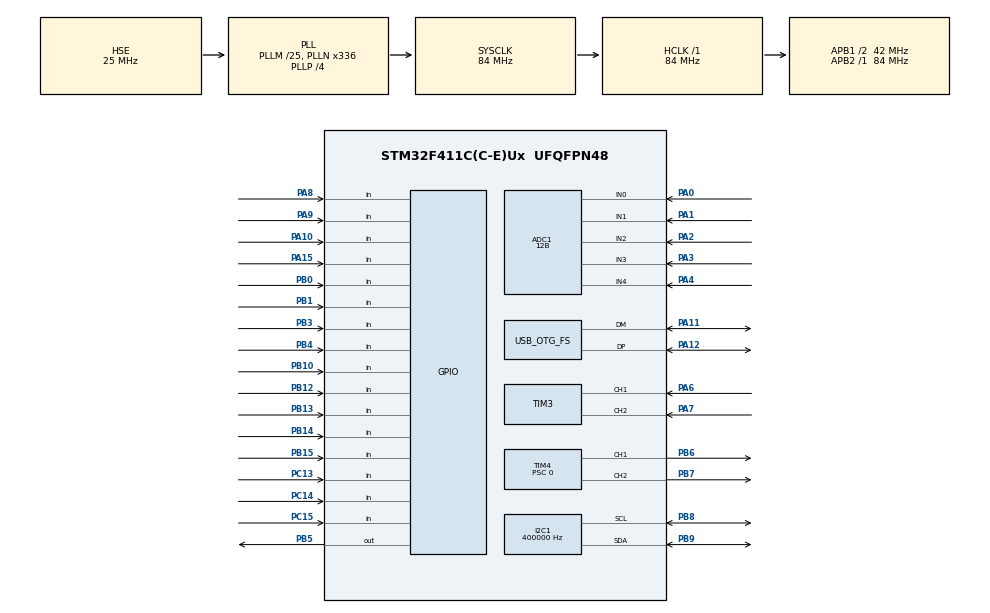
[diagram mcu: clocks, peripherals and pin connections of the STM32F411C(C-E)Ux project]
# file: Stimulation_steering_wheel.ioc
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ADC1.Channel-0\#ChannelRegularConversion=ADC_CHANNEL_0
ADC1.Channel-1\#ChannelRegularConversion=ADC_CHANNEL_1
ADC1.Channel-2\#ChannelRegularConversion=ADC_CHANNEL_2
ADC1.Channel-3\#ChannelRegularConversion=ADC_CHANNEL_3
ADC1.Channel-4\#ChannelRegularConversion=ADC_CHANNEL_4
ADC1.ClockPrescaler=ADC_CLOCK_SYNC_PCLK_DIV4
ADC1.ContinuousConvMode=DISABLE
ADC1.DMAContinuousRequests=DISABLE
ADC1.DataAlign=ADC_DATAALIGN_RIGHT
ADC1.DiscontinuousConvMode=DISABLE
ADC1.EOCSelection=ADC_EOC_SINGLE_CONV
ADC1.ExternalTrigConv=ADC_SOFTWARE_START
ADC1.ExternalTrigConvEdge=ADC_EXTERNALTRIGCONVEDGE_NONE
ADC1.NbrOfConversion=5
ADC1.NbrOfConversionFlag=1
ADC1.Rank-0\#ChannelRegularConversion=1
ADC1.Rank-1\#ChannelRegularConversion=2
ADC1.Rank-2\#ChannelRegularConversion=3
ADC1.Rank-3\#ChannelRegularConversion=4
ADC1.Rank-4\#ChannelRegularConversion=5
ADC1.Resolution=ADC_RESOLUTION_12B
ADC1.SamplingTime-0\#ChannelRegularConversion=ADC_SAMPLETIME_480CYCLES
ADC1.SamplingTime-1\#ChannelRegularConversion=ADC_SAMPLETIME_480CYCLES
ADC1.SamplingTime-2\#ChannelRegularConversion=ADC_SAMPLETIME_480CYCLES
ADC1.SamplingTime-3\#ChannelRegularConversion=ADC_SAMPLETIME_480CYCLES
ADC1.SamplingTime-4\#ChannelRegularConversion=ADC_SAMPLETIME_480CYCLES
ADC1.ScanConvMode=ENABLE
ADC1.master=1
I2C1.ClockSpeed=400000
I2C1.DutyCycle=I2C_DUTYCYCLE_2
I2C1.I2C_Mode=I2C_Fast
Mcu.Family=STM32F4
Mcu.Name=STM32F411C(C-E)Ux
Mcu.Package=UFQFPN48
NVIC.PriorityGroup=NVIC_PRIORITYGROUP_4
PA0-WKUP.Signal=ADCx_IN0
PA1.Signal=ADCx_IN1
PA10.GPIO_PuPd=GPIO_PULLUP
PA10.Signal=GPIO_Input
PA11.Mode=Device_Only
PA11.Signal=USB_OTG_FS_DM
PA12.Mode=Device_Only
PA12.Signal=USB_OTG_FS_DP
PA13.Mode=Serial_Wire
PA13.Signal=SYS_JTMS-SWDIO
PA14.Mode=Serial_Wire
PA14.Signal=SYS_JTCK-SWCLK
PA15.GPIO_PuPd=GPIO_PULLUP
PA15.Signal=GPIO_Input
PA2.Signal=ADCx_IN2
PA3.Signal=ADCx_IN3
PA4.Signal=ADCx_IN4
PA6.GPIO_PuPd=GPIO_PULLUP
PA6.Signal=S_TIM3_CH1
PA7.GPIO_PuPd=GPIO_PULLUP
PA7.Signal=S_TIM3_CH2
PA8.GPIO_PuPd=GPIO_PULLUP
PA8.Signal=GPIO_Input
PA9.GPIO_PuPd=GPIO_PULLUP
PA9.Signal=GPIO_Input
PB12.GPIO_PuPd=GPIO_PULLUP
PB12.Signal=GPIO_Input
PB13.GPIO_PuPd=GPIO_PULLUP
PB13.Signal=GPIO_Input
PB14.GPIO_PuPd=GPIO_PULLUP
PB14.Signal=GPIO_Input
PB15.GPIO_PuPd=GPIO_PULLUP
PB15.Signal=GPIO_Input
PB3.GPIO_PuPd=GPIO_PULLUP
PB3.Signal=GPIO_Input
PB4.GPIO_PuPd=GPIO_PULLUP
PB4.Signal=GPIO_Input
PB6.Signal=S_TIM4_CH1
PB7.Signal=S_TIM4_CH2
PB8.Mode=I2C
PB8.Signal=I2C1_SCL
PB9.Mode=I2C
PB9.Signal=I2C1_SDA
PB5.Signal=GPIO_Output
PH0\ -\ OSC_IN.Mode=HSE-External-Oscillator
PH0\ -\ OSC_IN.Signal=RCC_OSC_IN
PH1\ -\ OSC_OUT.Mode=HSE-External-Oscillator
PH1\ -\ OSC_OUT.Signal=RCC_OSC_OUT
ProjectManager.HeapSize=0x200
ProjectManager.StackSize=0x400
ProjectManager.TargetToolchain=MDK-ARM V5.32
RCC.48MHZClocksFreq_Value=48000000
RCC.AHBFreq_Value=84000000
RCC.APB1CLKDivider=RCC_HCLK_DIV2
RCC.APB1Freq_Value=42000000
RCC.APB1TimFreq_Value=84000000
RCC.APB2Freq_Value=84000000
RCC.APB2TimFreq_Value=84000000
RCC.CortexFreq_Value=84000000
RCC.HSE_VALUE=25000000
RCC.HSI_VALUE=16000000
RCC.LSE_VALUE=32768
RCC.PLLM=25
RCC.PLLN=336
RCC.PLLP=RCC_PLLP_DIV4
RCC.PLLQ=7
RCC.PLLSourceVirtual=RCC_PLLSOURCE_HSE
RCC.SYSCLKFreq_VALUE=84000000
RCC.SYSCLKSource=RCC_SYSCLKSOURCE_PLLCLK
RCC.VCOOutputFreq_Value=336000000
SH.ADCx_IN0.0=ADC1_IN0,IN0
SH.ADCx_IN1.0=ADC1_IN1,IN1
SH.ADCx_IN2.0=ADC1_IN2,IN2
SH.ADCx_IN3.0=ADC1_IN3,IN3
SH.ADCx_IN4.0=ADC1_IN4,IN4
SH.S_TIM3_CH1.0=TIM3_CH1,Encoder_Interface
SH.S_TIM3_CH2.0=TIM3_CH2,Encoder_Interface
SH.S_TIM4_CH1.0=TIM4_CH1,PWM Generation1 CH1
SH.S_TIM4_CH2.0=TIM4_CH2,PWM Generation2 CH2
TIM3.EncoderMode=TIM_ENCODERMODE_TI12
TIM3.IC1Filter=9
TIM3.IC1Prescaler=TIM_ICPSC_DIV1
TIM3.IC2Filter=9
TIM4.Channel-PWM\ Generation1\ CH1=TIM_CHANNEL_1
TIM4.Channel-PWM\ Generation2\ CH2=TIM_CHANNEL_2
TIM4.Period=4199
TIM4.Prescaler=0
USB_OTG_FS.VirtualMode=Device_Only
VP_TIM4_VS_ClockSourceINT.Mode=Internal
board=custom
PC13.GPIO_PuPd=GPIO_PULLUP
PC13.Signal=GPIO_Input
PC14-OSC32_IN.GPIO_PuPd=GPIO_PULLUP
PC14-OSC32_IN.Signal=GPIO_Input
PC15-OSC32_OUT.GPIO_PuPd=GPIO_PULLUP
PC15-OSC32_OUT.Signal=GPIO_Input
PB0.GPIO_PuPd=GPIO_PULLUP
PB0.Signal=GPIO_Input
PB1.GPIO_PuPd=GPIO_PULLUP
PB1.Signal=GPIO_Input
PB10.GPIO_PuPd=GPIO_PULLUP
PB10.Signal=GPIO_Input

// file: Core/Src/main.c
/* USER CODE BEGIN Header */
/**
  ******************************************************************************
  * @file           : main.c
  * @brief          : Main program body
  ******************************************************************************
  * @attention
  *
  * Copyright (c) 2026 STMicroelectronics.
  * All rights reserved.
  *
  * This software is licensed under terms that can be found in the LICENSE file
  * in the root directory of this software component.
  * If no LICENSE file comes with this software, it is provided AS-IS.
  *
  ******************************************************************************
  */
/* USER CODE END Header */
#include "main.h"

/* USER CODE BEGIN Includes */
#include "wheel.h"

/* USER CODE END Includes */

ADC_HandleTypeDef hadc1;
I2C_HandleTypeDef hi2c1;
TIM_HandleTypeDef htim3;
TIM_HandleTypeDef htim4;

void SystemClock_Config(void);
static void MX_GPIO_Init(void);
static void MX_ADC1_Init(void);
static void MX_I2C1_Init(void);
static void MX_TIM3_Init(void);
static void MX_TIM4_Init(void);

int main(void)
{

  /* MCU Configuration--------------------------------------------------------*/

  /* Reset of all peripherals, Initializes the Flash interface and the Systick. */
  HAL_Init();

  /* Configure the system clock */
  SystemClock_Config();

  /* Initialize all configured peripherals */
  MX_GPIO_Init();
  MX_ADC1_Init();
  MX_TIM3_Init();
  MX_TIM4_Init();
  MX_I2C1_Init();
  /* USER CODE BEGIN 2 */
  if (HAL_TIM_Encoder_Start(&htim3, TIM_CHANNEL_ALL) != HAL_OK)
  {
    Error_Handler();
  }
  /* Disable CCR preload so an emergency PWM stop takes effect immediately. */
  __HAL_TIM_DISABLE_OCxPRELOAD(&htim4, TIM_CHANNEL_1);
  __HAL_TIM_DISABLE_OCxPRELOAD(&htim4, TIM_CHANNEL_2);
  if (HAL_TIM_PWM_Start(&htim4, TIM_CHANNEL_1) != HAL_OK ||
      HAL_TIM_PWM_Start(&htim4, TIM_CHANNEL_2) != HAL_OK)
  {
    Error_Handler();
  }
  wheel_init();

  /* USER CODE END 2 */

  /* Infinite loop */
  while (1)
  {

    /* USER CODE BEGIN 3 */
    wheel_task();
  }
  /* USER CODE END 3 */
}

void SystemClock_Config(void)
{
  RCC_OscInitTypeDef RCC_OscInitStruct = {0};
  RCC_ClkInitTypeDef RCC_ClkInitStruct = {0};

  /** Configure the main internal regulator output voltage
  */
  __HAL_RCC_PWR_CLK_ENABLE();
  __HAL_PWR_VOLTAGESCALING_CONFIG(PWR_REGULATOR_VOLTAGE_SCALE2);

  /** Initializes the RCC Oscillators according to the specified parameters
  * in the RCC_OscInitTypeDef structure.
  */
  RCC_OscInitStruct.OscillatorType = RCC_OSCILLATORTYPE_HSE;
  RCC_OscInitStruct.HSEState = RCC_HSE_ON;
  RCC_OscInitStruct.PLL.PLLState = RCC_PLL_ON;
  RCC_OscInitStruct.PLL.PLLSource = RCC_PLLSOURCE_HSE;
  RCC_OscInitStruct.PLL.PLLM = 25;
  RCC_OscInitStruct.PLL.PLLN = 336;
  RCC_OscInitStruct.PLL.PLLP = RCC_PLLP_DIV4;
  RCC_OscInitStruct.PLL.PLLQ = 7;
  if (HAL_RCC_OscConfig(&RCC_OscInitStruct) != HAL_OK)
  {
    Error_Handler();
  }

  /** Initializes the CPU, AHB and APB buses clocks
  */
  RCC_ClkInitStruct.ClockType = RCC_CLOCKTYPE_HCLK|RCC_CLOCKTYPE_SYSCLK
                              |RCC_CLOCKTYPE_PCLK1|RCC_CLOCKTYPE_PCLK2;
  RCC_ClkInitStruct.SYSCLKSource = RCC_SYSCLKSOURCE_PLLCLK;
  RCC_ClkInitStruct.AHBCLKDivider = RCC_SYSCLK_DIV1;
  RCC_ClkInitStruct.APB1CLKDivider = RCC_HCLK_DIV2;
  RCC_ClkInitStruct.APB2CLKDivider = RCC_HCLK_DIV1;

  if (HAL_RCC_ClockConfig(&RCC_ClkInitStruct, FLASH_LATENCY_2) != HAL_OK)
  {
    Error_Handler();
  }
}

static void MX_TIM3_Init(void)
{

  TIM_Encoder_InitTypeDef sConfig = {0};
  TIM_MasterConfigTypeDef sMasterConfig = {0};

  htim3.Instance = TIM3;
  htim3.Init.Prescaler = 0;
  htim3.Init.CounterMode = TIM_COUNTERMODE_UP;
  htim3.Init.Period = 65535;
  htim3.Init.ClockDivision = TIM_CLOCKDIVISION_DIV1;
  htim3.Init.AutoReloadPreload = TIM_AUTORELOAD_PRELOAD_DISABLE;
  sConfig.EncoderMode = TIM_ENCODERMODE_TI12;
  sConfig.IC1Selection = TIM_ICSELECTION_DIRECTTI;
  sConfig.IC2Selection = TIM_ICSELECTION_DIRECTTI;
  sConfig.IC2Polarity = TIM_ICPOLARITY_RISING;
  sConfig.IC2Prescaler = TIM_ICPSC_DIV1;
  sConfig.IC2Filter = 9;
  sConfig.IC1Polarity = TIM_ICPOLARITY_RISING;
  sConfig.IC1Prescaler = TIM_ICPSC_DIV1;
  sConfig.IC1Filter = 9;
  if (HAL_TIM_Encoder_Init(&htim3, &sConfig) != HAL_OK)
  {
    Error_Handler();
  }
  sMasterConfig.MasterOutputTrigger = TIM_TRGO_RESET;
  sMasterConfig.MasterSlaveMode = TIM_MASTERSLAVEMODE_DISABLE;
  if (HAL_TIMEx_MasterConfigSynchronization(&htim3, &sMasterConfig) != HAL_OK)
  {
    Error_Handler();
  }

}

static void MX_TIM4_Init(void)
{

  TIM_ClockConfigTypeDef sClockSourceConfig = {0};
  TIM_MasterConfigTypeDef sMasterConfig = {0};
  TIM_OC_InitTypeDef sConfigOC = {0};

  htim4.Instance = TIM4;
  htim4.Init.Prescaler = 0;
  htim4.Init.CounterMode = TIM_COUNTERMODE_UP;
  htim4.Init.Period = 4199;
  htim4.Init.ClockDivision = TIM_CLOCKDIVISION_DIV1;
  htim4.Init.AutoReloadPreload = TIM_AUTORELOAD_PRELOAD_DISABLE;
  if (HAL_TIM_Base_Init(&htim4) != HAL_OK)
  {
    Error_Handler();
  }
  sClockSourceConfig.ClockSource = TIM_CLOCKSOURCE_INTERNAL;
  if (HAL_TIM_ConfigClockSource(&htim4, &sClockSourceConfig) != HAL_OK)
  {
    Error_Handler();
  }
  if (HAL_TIM_PWM_Init(&htim4) != HAL_OK)
  {
    Error_Handler();
  }
  sMasterConfig.MasterOutputTrigger = TIM_TRGO_RESET;
  sMasterConfig.MasterSlaveMode = TIM_MASTERSLAVEMODE_DISABLE;
  if (HAL_TIMEx_MasterConfigSynchronization(&htim4, &sMasterConfig) != HAL_OK)
  {
    Error_Handler();
  }
  sConfigOC.OCMode = TIM_OCMODE_PWM1;
  sConfigOC.Pulse = 0;
  sConfigOC.OCPolarity = TIM_OCPOLARITY_HIGH;
  sConfigOC.OCFastMode = TIM_OCFAST_DISABLE;
  if (HAL_TIM_PWM_ConfigChannel(&htim4, &sConfigOC, TIM_CHANNEL_1) != HAL_OK)
  {
    Error_Handler();
  }
  if (HAL_TIM_PWM_ConfigChannel(&htim4, &sConfigOC, TIM_CHANNEL_2) != HAL_OK)
  {
    Error_Handler();
  }
  HAL_TIM_MspPostInit(&htim4);

}

static void MX_I2C1_Init(void)
{
  hi2c1.Instance = I2C1;
  hi2c1.Init.ClockSpeed = 400000;
  hi2c1.Init.DutyCycle = I2C_DUTYCYCLE_2;
  hi2c1.Init.OwnAddress1 = 0;
  hi2c1.Init.AddressingMode = I2C_ADDRESSINGMODE_7BIT;
  hi2c1.Init.DualAddressMode = I2C_DUALADDRESS_DISABLE;
  hi2c1.Init.OwnAddress2 = 0;
  hi2c1.Init.GeneralCallMode = I2C_GENERALCALL_DISABLE;
  hi2c1.Init.NoStretchMode = I2C_NOSTRETCH_DISABLE;
  if (HAL_I2C_Init(&hi2c1) != HAL_OK) Error_Handler();
}

static void MX_ADC1_Init(void)
{
  ADC_ChannelConfTypeDef channel = {0};
  hadc1.Instance = ADC1;
  hadc1.Init.ClockPrescaler = ADC_CLOCK_SYNC_PCLK_DIV4;
  hadc1.Init.Resolution = ADC_RESOLUTION_12B;
  hadc1.Init.ScanConvMode = ENABLE;
  hadc1.Init.ContinuousConvMode = DISABLE;
  hadc1.Init.DiscontinuousConvMode = DISABLE;
  hadc1.Init.ExternalTrigConvEdge = ADC_EXTERNALTRIGCONVEDGE_NONE;
  hadc1.Init.ExternalTrigConv = ADC_SOFTWARE_START;
  hadc1.Init.DataAlign = ADC_DATAALIGN_RIGHT;
  hadc1.Init.NbrOfConversion = 5;
  hadc1.Init.DMAContinuousRequests = DISABLE;
  hadc1.Init.EOCSelection = ADC_EOC_SINGLE_CONV;
  if (HAL_ADC_Init(&hadc1) != HAL_OK)
  {
    Error_Handler();
  }
  channel.Channel = ADC_CHANNEL_0;
  channel.Rank = 1;
  channel.SamplingTime = ADC_SAMPLETIME_480CYCLES;
  if (HAL_ADC_ConfigChannel(&hadc1, &channel) != HAL_OK)
  {
    Error_Handler();
  }
  channel.Channel = ADC_CHANNEL_1;
  channel.Rank = 2;
  if (HAL_ADC_ConfigChannel(&hadc1, &channel) != HAL_OK)
  {
    Error_Handler();
  }
  channel.Channel = ADC_CHANNEL_2;
  channel.Rank = 3;
  if (HAL_ADC_ConfigChannel(&hadc1, &channel) != HAL_OK)
  {
    Error_Handler();
  }
  channel.Channel = ADC_CHANNEL_3;
  channel.Rank = 4;
  if (HAL_ADC_ConfigChannel(&hadc1, &channel) != HAL_OK)
  {
    Error_Handler();
  }
  channel.Channel = ADC_CHANNEL_4;
  channel.Rank = 5;
  if (HAL_ADC_ConfigChannel(&hadc1, &channel) != HAL_OK)
  {
    Error_Handler();
  }
}

static void MX_GPIO_Init(void)
{
  GPIO_InitTypeDef GPIO_InitStruct = {0};

  /* GPIO Ports Clock Enable */
  __HAL_RCC_GPIOH_CLK_ENABLE();
  __HAL_RCC_GPIOC_CLK_ENABLE();
  __HAL_RCC_GPIOA_CLK_ENABLE();
  __HAL_RCC_GPIOB_CLK_ENABLE();

  /*Configure GPIO pin Output Level */
  HAL_GPIO_WritePin(GPIOB, GPIO_PIN_5, GPIO_PIN_RESET);

  /* Active-low Shift down, Fn2, Fn4 and Fn7. */
  GPIO_InitStruct.Pin = GPIO_PIN_8|GPIO_PIN_9|GPIO_PIN_10|GPIO_PIN_15;
  GPIO_InitStruct.Mode = GPIO_MODE_INPUT;
  GPIO_InitStruct.Pull = GPIO_PULLUP;
  HAL_GPIO_Init(GPIOA, &GPIO_InitStruct);

  /* Active-low Shift up, Fn1, Fn3, Fn5, Fn6 and Fn8. */
  GPIO_InitStruct.Pin = GPIO_PIN_0|GPIO_PIN_1|GPIO_PIN_3|GPIO_PIN_4
                      |GPIO_PIN_10|GPIO_PIN_12|GPIO_PIN_13|GPIO_PIN_14|GPIO_PIN_15;
  HAL_GPIO_Init(GPIOB, &GPIO_InitStruct);

  /* Gear 1, Gear 2 and Gear 3. LSE is unused. */
  GPIO_InitStruct.Pin = GPIO_PIN_13|GPIO_PIN_14|GPIO_PIN_15;
  HAL_GPIO_Init(GPIOC, &GPIO_InitStruct);

  /* BTS7960 R_EN and L_EN share PB5. */
  GPIO_InitStruct.Pin = GPIO_PIN_5;
  GPIO_InitStruct.Mode = GPIO_MODE_OUTPUT_PP;
  GPIO_InitStruct.Pull = GPIO_NOPULL;
  GPIO_InitStruct.Speed = GPIO_SPEED_FREQ_LOW;
  HAL_GPIO_Init(GPIOB, &GPIO_InitStruct);

}

void Error_Handler(void)
{
  __disable_irq();
  while (1)
  {
  }
}
